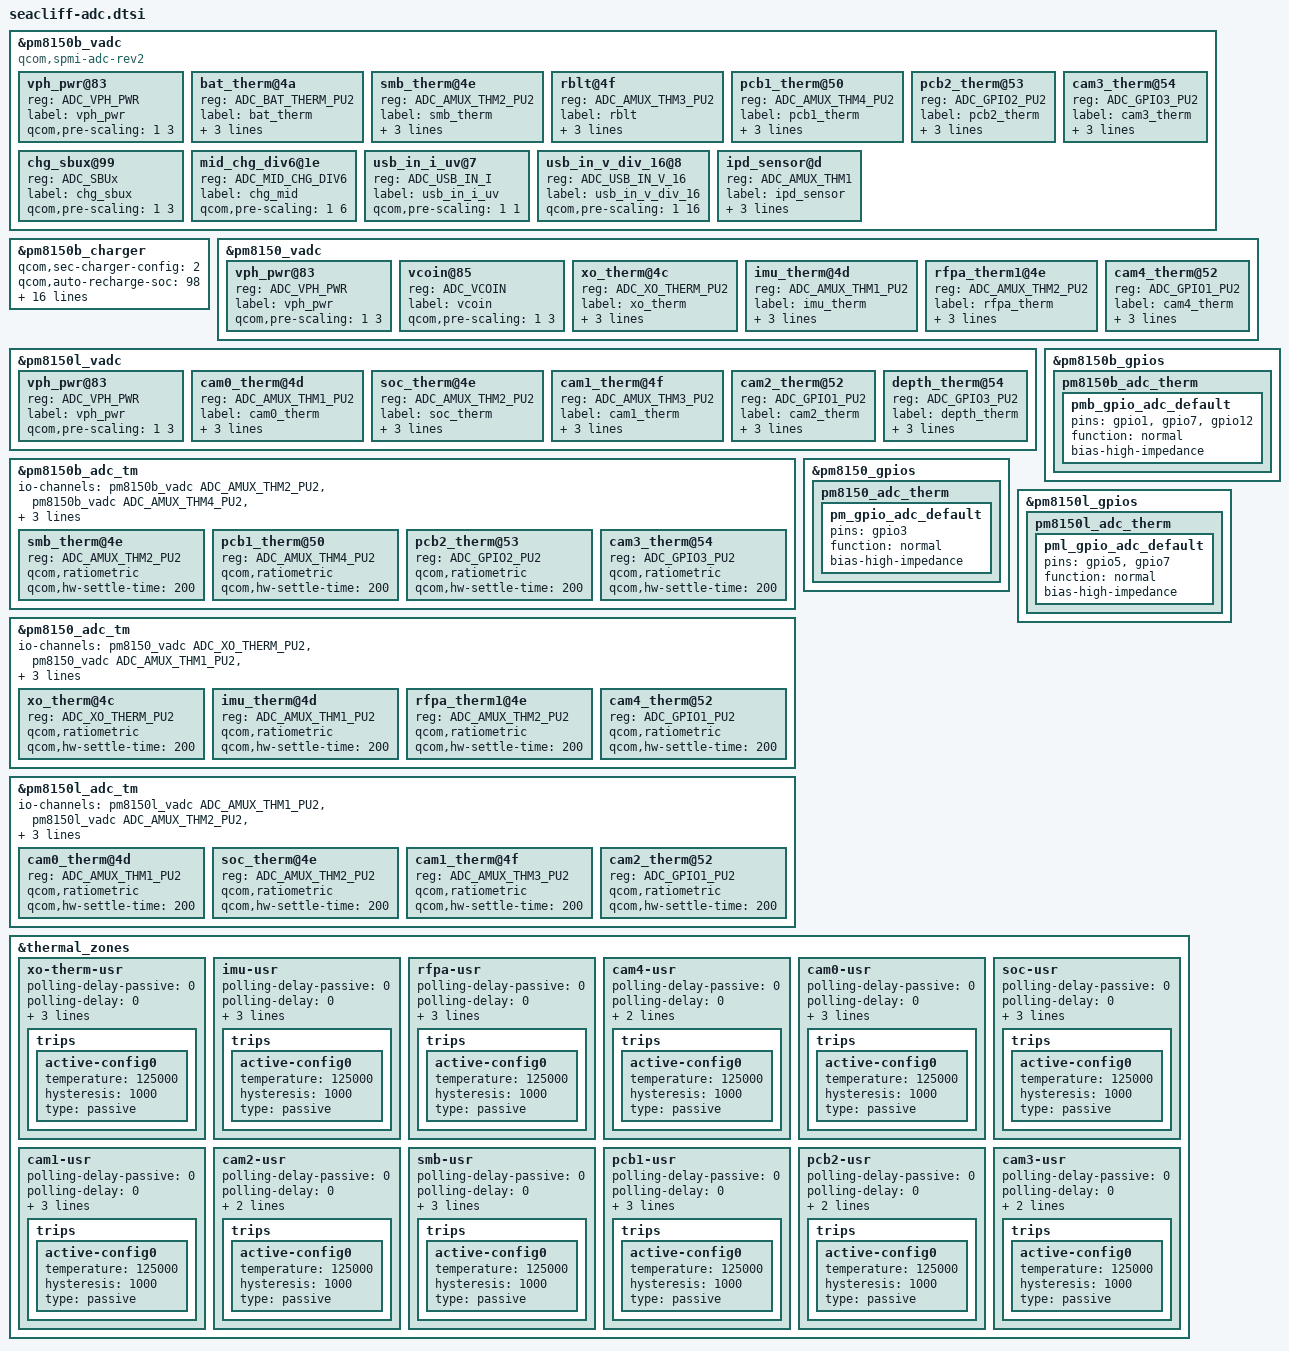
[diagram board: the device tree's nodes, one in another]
&pm8150b_vadc {
	#address-cells = <1>;
	#size-cells = <0>;
	compatible = "qcom,spmi-adc-rev2";
	vph_pwr@83 {
		reg = <ADC_VPH_PWR>;
		label = "vph_pwr";
		qcom,pre-scaling = <1 3>;
	};

	bat_therm@4a {
		reg = <ADC_BAT_THERM_PU2>;
		label = "bat_therm";
		qcom,ratiometric;
		qcom,hw-settle-time = <200>;
		qcom,pre-scaling = <1 1>;
	};

	smb_therm@4e {
		reg = <ADC_AMUX_THM2_PU2>;
		label = "smb_therm";
		qcom,ratiometric;
		qcom,hw-settle-time = <200>;
		qcom,pre-scaling = <1 1>;
	};

	rblt@4f {
		reg = <ADC_AMUX_THM3_PU2>;
		label = "rblt";
		qcom,ratiometric;
		qcom,hw-settle-time = <200>;
		qcom,pre-scaling = <1 1>;
	};

	pcb1_therm@50 {
		reg = <ADC_AMUX_THM4_PU2>;
		label = "pcb1_therm";
		qcom,ratiometric;
		qcom,hw-settle-time = <200>;
		qcom,pre-scaling = <1 1>;
	};

	pcb2_therm@53 {
		reg = <ADC_GPIO2_PU2>;
		label = "pcb2_therm";
		qcom,ratiometric;
		qcom,hw-settle-time = <200>;
		qcom,pre-scaling = <1 1>;
	};

	cam3_therm@54 {
		/* Canyon right */
		reg = <ADC_GPIO3_PU2>;
		label = "cam3_therm";
		qcom,ratiometric;
		qcom,hw-settle-time = <200>;
		qcom,pre-scaling = <1 1>;
	};

	chg_sbux@99 {
		reg = <ADC_SBUx>;
		label = "chg_sbux";
		qcom,pre-scaling = <1 3>;
	};

	mid_chg_div6@1e {
		reg = <ADC_MID_CHG_DIV6>;
		label = "chg_mid";
		qcom,pre-scaling = <1 6>;
	};

	usb_in_i_uv@7 {
		reg = <ADC_USB_IN_I>;
		label = "usb_in_i_uv";
		qcom,pre-scaling = <1 1>;
	};

	usb_in_v_div_16@8 {
		reg = <ADC_USB_IN_V_16>;
		label = "usb_in_v_div_16";
		qcom,pre-scaling = <1 16>;
	};

	ipd_sensor@d {
		reg = <ADC_AMUX_THM1>;
		label = "ipd_sensor";
		qcom,hw-settle-time = <200>;
		qcom,pre-scaling = <1 1>;
		qcom,decimation = <1024>;
	};
};

&pm8150b_charger {
	status = "ok";
	qcom,sec-charger-config = <2>;
	qcom,auto-recharge-soc = <98>;
	io-channels = <&pm8150b_vadc ADC_USB_IN_V_16>,
		      <&pm8150b_vadc ADC_MID_CHG_DIV6>,
		      <&pm8150b_vadc ADC_USB_IN_I>,
		      <&pm8150b_vadc ADC_SBUx>,
		      <&pm8150b_vadc ADC_VPH_PWR>,
		      <&pm8150b_vadc ADC_CHG_TEMP>,
		      <&pm8150b_vadc ADC_AMUX_THM3_PU2>;
	io-channel-names = "usb_in_voltage",
			   "mid_voltage",
			   "usb_in_current",
			   "sbux_res",
			   "vph_voltage",
			   "chg_temp",
			   "rblt_res";
	qcom,battery-data = <&kona_mtp_batterydata>;
	qcom,step-charging-enable;
	qcom,sw-jeita-enable;
	qcom,wd-bark-time-secs = <16>;
	qcom,suspend-input-on-debug-batt;
	qcom,fcc-max-ua = <4813000>;
	qcom,usb-icl-ua = <3000000>;
	qcom,dc-icl-ua = <3000000>;
	qcom,typec-dam-enable;
};

&pm8150_vadc {
	#address-cells = <1>;
	#size-cells = <0>;

	vph_pwr@83 {
		reg = <ADC_VPH_PWR>;
		label = "vph_pwr";
		qcom,pre-scaling = <1 3>;
	};

	vcoin@85 {
		reg = <ADC_VCOIN>;
		label = "vcoin";
		qcom,pre-scaling = <1 3>;
	};

	xo_therm@4c {
		reg = <ADC_XO_THERM_PU2>;
		label = "xo_therm";
		qcom,ratiometric;
		qcom,hw-settle-time = <200>;
		qcom,pre-scaling = <1 1>;
	};

	imu_therm@4d {
		reg = <ADC_AMUX_THM1_PU2>;
		label = "imu_therm";
		qcom,ratiometric;
		qcom,hw-settle-time = <200>;
		qcom,pre-scaling = <1 1>;
	};

	rfpa_therm1@4e {
		reg = <ADC_AMUX_THM2_PU2>;
		label = "rfpa_therm";
		qcom,ratiometric;
		qcom,hw-settle-time = <200>;
		qcom,pre-scaling = <1 1>;
	};

	cam4_therm@52 {
		/* Teton */
		reg = <ADC_GPIO1_PU2>;
		label = "cam4_therm";
		qcom,ratiometric;
		qcom,hw-settle-time = <200>;
		qcom,pre-scaling = <1 1>;
	};
};

&pm8150l_vadc {
	#address-cells = <1>;
	#size-cells = <0>;

	vph_pwr@83 {
		reg = <ADC_VPH_PWR>;
		label = "vph_pwr";
		qcom,pre-scaling = <1 3>;
	};

	cam0_therm@4d {
		/* Glacier left */
		reg = <ADC_AMUX_THM1_PU2>;
		label = "cam0_therm";
		qcom,ratiometric;
		qcom,hw-settle-time = <200>;
		qcom,pre-scaling = <1 1>;
	};

	soc_therm@4e {
		reg = <ADC_AMUX_THM2_PU2>;
		label = "soc_therm";
		qcom,ratiometric;
		qcom,hw-settle-time = <200>;
		qcom,pre-scaling = <1 1>;
	};

	cam1_therm@4f {
		/* Glacier right */
		reg = <ADC_AMUX_THM3_PU2>;
		label = "cam1_therm";
		qcom,ratiometric;
		qcom,hw-settle-time = <200>;
		qcom,pre-scaling = <1 1>;
	};

	cam2_therm@52 {
		/* Canyon left */
		reg = <ADC_GPIO1_PU2>;
		label = "cam2_therm";
		qcom,ratiometric;
		qcom,hw-settle-time = <200>;
		qcom,pre-scaling = <1 1>;
	};

	depth_therm@54 {
		reg = <ADC_GPIO3_PU2>;
		label = "depth_therm";
		qcom,ratiometric;
		qcom,hw-settle-time = <200>;
		qcom,pre-scaling = <1 1>;
	};
};

&pm8150b_gpios {
	pm8150b_adc_therm {
		pmb_gpio_adc_default: pmb_gpio_adc_default {
			pins = "gpio1", "gpio7", "gpio12";
			function = "normal";
			bias-high-impedance;
		};
	};
};

&pm8150b_adc_tm {
	#address-cells = <1>;
	#size-cells = <0>;

	io-channels = <&pm8150b_vadc ADC_AMUX_THM2_PU2>,
		<&pm8150b_vadc ADC_AMUX_THM4_PU2>,
		<&pm8150b_vadc ADC_GPIO2_PU2>,
		<&pm8150b_vadc ADC_GPIO3_PU2>;

	pinctrl-names = "default";
	pinctrl-0 = <&pmb_gpio_adc_default>;

	smb_therm@4e {
		reg = <ADC_AMUX_THM2_PU2>;
		qcom,ratiometric;
		qcom,hw-settle-time = <200>;
	};

	pcb1_therm@50 {
		reg = <ADC_AMUX_THM4_PU2>;
		qcom,ratiometric;
		qcom,hw-settle-time = <200>;
	};

	pcb2_therm@53 {
		reg = <ADC_GPIO2_PU2>;
		qcom,ratiometric;
		qcom,hw-settle-time = <200>;
	};

	cam3_therm@54 {
		/* Canyon right */
		reg = <ADC_GPIO3_PU2>;
		qcom,ratiometric;
		qcom,hw-settle-time = <200>;
	};
};

&pm8150_gpios {
	pm8150_adc_therm {
		pm_gpio_adc_default: pm_gpio_adc_default {
			pins = "gpio3";
			function = "normal";
			bias-high-impedance;
		};
	};
};

&pm8150_adc_tm {
	#address-cells = <1>;
	#size-cells = <0>;

	io-channels = <&pm8150_vadc ADC_XO_THERM_PU2>,
			<&pm8150_vadc ADC_AMUX_THM1_PU2>,
			<&pm8150_vadc ADC_AMUX_THM2_PU2>,
			<&pm8150_vadc ADC_GPIO1_PU2>;

	pinctrl-names = "default";
	pinctrl-0 = <&pm_gpio_adc_default>;

	xo_therm@4c {
		reg = <ADC_XO_THERM_PU2>;
		qcom,ratiometric;
		qcom,hw-settle-time = <200>;
	};

	imu_therm@4d {
		reg = <ADC_AMUX_THM1_PU2>;
		qcom,ratiometric;
		qcom,hw-settle-time = <200>;
	};

	rfpa_therm1@4e {
		reg = <ADC_AMUX_THM2_PU2>;
		qcom,ratiometric;
		qcom,hw-settle-time = <200>;
	};

	cam4_therm@52 {
		/* Teton */
		reg = <ADC_GPIO1_PU2>;
		qcom,ratiometric;
		qcom,hw-settle-time = <200>;
	};
};

&pm8150l_gpios {
	pm8150l_adc_therm {
		pml_gpio_adc_default: pml_gpio_adc_default {
			pins = "gpio5", "gpio7";
			function = "normal";
			bias-high-impedance;
		};
	};
};

&pm8150l_adc_tm {
	#address-cells = <1>;
	#size-cells = <0>;

	io-channels = <&pm8150l_vadc ADC_AMUX_THM1_PU2>,
		<&pm8150l_vadc ADC_AMUX_THM2_PU2>,
		<&pm8150l_vadc ADC_AMUX_THM3_PU2>,
		<&pm8150l_vadc ADC_GPIO1_PU2>;

	pinctrl-names = "default";
	pinctrl-0 = <&pml_gpio_adc_default>;

	cam0_therm@4d {
		/* Glacier left */
		reg = <ADC_AMUX_THM1_PU2>;
		qcom,ratiometric;
		qcom,hw-settle-time = <200>;
	};

	soc_therm@4e {
		reg = <ADC_AMUX_THM2_PU2>;
		qcom,ratiometric;
		qcom,hw-settle-time = <200>;
	};

	cam1_therm@4f {
		/* Glacier right */
		reg = <ADC_AMUX_THM3_PU2>;
		qcom,ratiometric;
		qcom,hw-settle-time = <200>;
	};

	cam2_therm@52 {
		/* Canyon left */
		reg = <ADC_GPIO1_PU2>;
		qcom,ratiometric;
		qcom,hw-settle-time = <200>;
	};
};

&thermal_zones {
	xo-therm-usr {
		polling-delay-passive = <0>;
		polling-delay = <0>;
		thermal-governor = "user_space";
		thermal-sensors = <&pm8150_adc_tm ADC_XO_THERM_PU2>;
		trips {
			active-config0 {
				temperature = <125000>;
				hysteresis = <1000>;
				type = "passive";
			};
		};
	};

	imu-usr {
		polling-delay-passive = <0>;
		polling-delay = <0>;
		thermal-governor = "user_space";
		thermal-sensors = <&pm8150_adc_tm ADC_AMUX_THM1_PU2>;
		trips {
			active-config0 {
				temperature = <125000>;
				hysteresis = <1000>;
				type = "passive";
			};
		};
	};

	rfpa-usr {
		polling-delay-passive = <0>;
		polling-delay = <0>;
		thermal-governor = "user_space";
		thermal-sensors = <&pm8150_adc_tm ADC_AMUX_THM2_PU2>;
		trips {
			active-config0 {
				temperature = <125000>;
				hysteresis = <1000>;
				type = "passive";
			};
		};
	};

	cam4-usr {
		/* Teton */
		polling-delay-passive = <0>;
		polling-delay = <0>;
		thermal-governor = "user_space";
		thermal-sensors = <&pm8150_adc_tm ADC_GPIO1_PU2>;
		trips {
			active-config0 {
				temperature = <125000>;
				hysteresis = <1000>;
				type = "passive";
			};
		};
	};

	cam0-usr {
		/* Glacier left */
		polling-delay-passive = <0>;
		polling-delay = <0>;
		thermal-governor = "user_space";
		thermal-sensors = <&pm8150l_adc_tm ADC_AMUX_THM1_PU2>;
		trips {
			active-config0 {
				temperature = <125000>;
				hysteresis = <1000>;
				type = "passive";
			};
		};
	};

	soc-usr {
		polling-delay-passive = <0>;
		polling-delay = <0>;
		thermal-governor = "user_space";
		thermal-sensors = <&pm8150l_adc_tm ADC_AMUX_THM2_PU2>;
		trips {
			active-config0 {
				temperature = <125000>;
				hysteresis = <1000>;
				type = "passive";
			};
		};
	};

	cam1-usr {
		/* Glacier right */
		polling-delay-passive = <0>;
		polling-delay = <0>;
		thermal-governor = "user_space";
		thermal-sensors = <&pm8150l_adc_tm ADC_AMUX_THM3_PU2>;
		trips {
			active-config0 {
				temperature = <125000>;
				hysteresis = <1000>;
				type = "passive";
			};
		};
	};

	cam2-usr {
		/* Canyon left */
		polling-delay-passive = <0>;
		polling-delay = <0>;
		thermal-governor = "user_space";
		thermal-sensors = <&pm8150l_adc_tm ADC_GPIO1_PU2>;
		trips {
			active-config0 {
				temperature = <125000>;
				hysteresis = <1000>;
				type = "passive";
			};
		};
	};

	smb-usr {
		polling-delay-passive = <0>;
		polling-delay = <0>;
		thermal-governor = "user_space";
		thermal-sensors = <&pm8150b_adc_tm ADC_AMUX_THM2_PU2>;
		trips {
			active-config0 {
				temperature = <125000>;
				hysteresis = <1000>;
				type = "passive";
			};
		};
	};

	pcb1-usr {
		polling-delay-passive = <0>;
		polling-delay = <0>;
		thermal-governor = "user_space";
		thermal-sensors = <&pm8150b_adc_tm ADC_AMUX_THM4_PU2>;
		trips {
			active-config0 {
				temperature = <125000>;
				hysteresis = <1000>;
				type = "passive";
			};
		};
	};

	pcb2-usr {
		polling-delay-passive = <0>;
		polling-delay = <0>;
		thermal-governor = "user_space";
		thermal-sensors = <&pm8150b_adc_tm ADC_GPIO2_PU2>;
		trips {
			active-config0 {
				temperature = <125000>;
				hysteresis = <1000>;
				type = "passive";
			};
		};
	};

	cam3-usr {
		/* Canyon right */
		polling-delay-passive = <0>;
		polling-delay = <0>;
		thermal-governor = "user_space";
		thermal-sensors = <&pm8150b_adc_tm ADC_GPIO3_PU2>;
		trips {
			active-config0 {
				temperature = <125000>;
				hysteresis = <1000>;
				type = "passive";
			};
		};
	};
};
